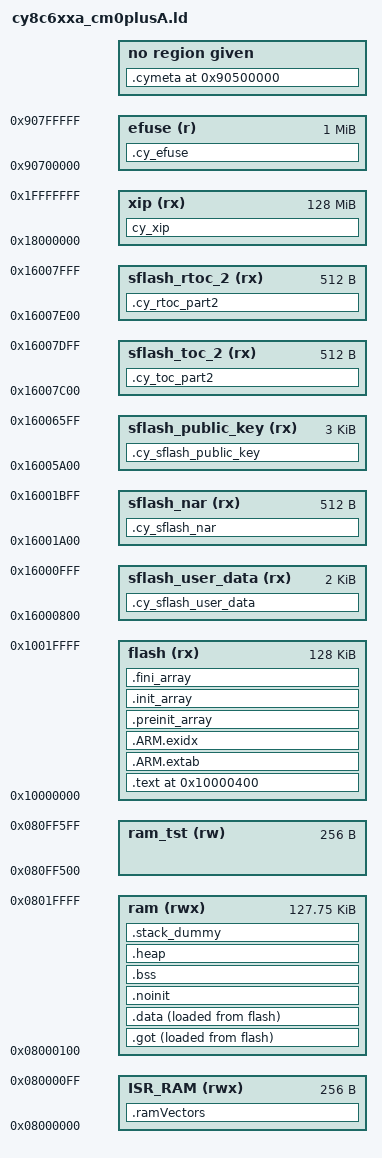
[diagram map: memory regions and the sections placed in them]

/**       ___
 *   ___ / _ \
 *  / _ ' (_) |       __  _
 * | (_) ,___/       / _|(_)
 *  \___/  _  _ __  | |_  _  _ __    ___  _ __  __ _
 *        | || '_ \ |  _|| || '_ \  / _ \| '__|/ _' |
 *        | || | | || |  | || | | ||  __/| |  | (_| |
 *        |_||_| |_||_|  |_||_| |_| \___||_|   \__,_|
 *
 * @file cy8c6xxa_cm0plusA.ld            @brief linker script
 *
 * @author Autogenerated
 *
 * @copyright 2023 Infinera. All rights reserved.
 * Infinera Proprietary and Confidential.
 *
 * @details
 * This file was generated automatically, src cy8c6xxa_cm0plusA.ld.in for details
 * Please do not modify it manually
 *
 ***************************************************************************/

OUTPUT_FORMAT ("elf32-littlearm", "elf32-bigarm", "elf32-littlearm")
SEARCH_DIR(.)
GROUP(-lgcc -lc -lnosys)
ENTRY(Reset_Handler)


STACK_SIZE = 0x1000;






EXTERN(Reset_Handler)




MEMORY
{







    ISR_RAM (rwx) : ORIGIN = 0x08000000, LENGTH = 0x100
    ram (rwx) : ORIGIN = 0x08000100, LENGTH = 0x1FF00
    ram_tst (rw) : ORIGIN = 0x080FF500, LENGTH = 0x100
    flash (rx) : ORIGIN = (0x10000000), LENGTH = 0x20000
    sflash_user_data (rx) : ORIGIN = 0x16000800, LENGTH = 0x800
    sflash_nar (rx) : ORIGIN = 0x16001A00, LENGTH = 0x200
    sflash_public_key (rx) : ORIGIN = 0x16005A00, LENGTH = 0xC00
    sflash_toc_2 (rx) : ORIGIN = 0x16007C00, LENGTH = 0x200
    sflash_rtoc_2 (rx) : ORIGIN = 0x16007E00, LENGTH = 0x200
    xip (rx) : ORIGIN = 0x18000000, LENGTH = 0x8000000
    efuse (r) : ORIGIN = 0x90700000, LENGTH = 0x100000
}
__flash_begin = ORIGIN(flash) + 0x400;
__flash_end = ORIGIN(flash) + LENGTH(flash);


GROUP(libgcc.a libc.a libm.a libnosys.a)
SECTIONS
{

    .text ORIGIN(flash) + 0x400 :
    {
       __flash_vector_table_begin = . ;
       KEEP(*(.vectors))
       __flash_vector_table_end = .;

        *(.text*)

        KEEP(*(.init))
        KEEP(*(.fini))


        *crtbegin.o(.ctors)
        *crtbegin?.o(.ctors)
        *(EXCLUDE_FILE(*crtend?.o *crtend.o) .ctors)
        *(SORT(.ctors.*))
        *(.ctors)


        *crtbegin.o(.dtors)
        *crtbegin?.o(.dtors)
        *(EXCLUDE_FILE(*crtend?.o *crtend.o) .dtors)
        *(SORT(.dtors.*))
        *(.dtors)


        *(.rodata .rodata.* .constdata .constdata.* .conststring .conststring.*)

        KEEP(*(.eh_frame*))
        _etext = .;
    } > flash

    .ramVectors (NOLOAD) : ALIGN(8)
    {
        __ram_vector_table_begin = .;
        KEEP(*(.ram_vectors))
        __ram_vector_table_end = .;
    } >ISR_RAM


    .got :
    {
        . = ALIGN(4);
        *(.got)
        *(.got.plt)
        KEEP(*(.igot.plt))
        . = ALIGN(4);
    } >ram AT > flash
    __flash_global_offset_table_begin = LOADADDR(.got) ;
    __flash_global_offset_table_end = __flash_global_offset_table_begin + SIZEOF(.got) ;
    __ram_global_offset_table_begin = ADDR(.got) ;
    __ram_global_offset_table_end = __ram_global_offset_table_begin + SIZEOF(.got) ;


    .ARM.extab :
    {
        . = ALIGN(4);
        *(.ARM.extab* .gnu.linkonce.armextab.*)
        . = ALIGN(4);
    } > flash

    .ARM.exidx :
    {
        . = ALIGN(4);
        __exidx_start = .;
        *(.ARM.exidx* .gnu.linkonce.armexidx.*)
        __exidx_end = .;
    } > flash

    .preinit_array :
  {
    . = ALIGN(4);
    PROVIDE_HIDDEN (__preinit_array_start = .);
    KEEP (*(.preinit_array*))
    PROVIDE_HIDDEN (__preinit_array_end = .);
    . = ALIGN(4);
  } >flash

  .init_array :
  {
    . = ALIGN(4);
    PROVIDE_HIDDEN (__init_array_start = .);
    KEEP (*(SORT(.init_array.*)))
    KEEP (*(.init_array*))
    PROVIDE_HIDDEN (__init_array_end = .);
    . = ALIGN(4);
  } >flash

  .fini_array :
  {
    . = ALIGN(4);
    PROVIDE_HIDDEN (__fini_array_start = .);
    KEEP (*(SORT(.fini_array.*)))
    KEEP (*(.fini_array*))
    PROVIDE_HIDDEN (__fini_array_end = .);
    . = ALIGN(4);
  } >flash


    _sidata = LOADADDR(.data);
    .data :
    {
        . = ALIGN(4);
        __data_start__ = .;

        *(vtable)
        *(.data*)

        . = ALIGN(4);
        KEEP(*(.jcr*))
        . = ALIGN(4);

        KEEP(*(.cy_ramfunc*))
        . = ALIGN(4);

        __data_end__ = .;

    } > ram AT>flash





    .noinit (NOLOAD) : ALIGN(8)
    {
      KEEP(*(.noinit))
    } > ram
    .bss (NOLOAD):
    {
        . = ALIGN(4);
        __bss_start__ = .;
        *(.bss*)
        *(COMMON)
        . = ALIGN(4);
        __bss_end__ = .;
    } > ram


    .heap (NOLOAD):
    {
        __HeapBase = .;
        __end__ = .;
        end = __end__;
        KEEP(*(.heap*))
        . = ORIGIN(ram) + LENGTH(ram) - STACK_SIZE;
        __HeapLimit = .;
    } > ram




    .stack_dummy (NOLOAD):
    {
        KEEP(*(.stack*))
    } > ram




    __StackTop = ORIGIN(ram) + LENGTH(ram);
    __StackLimit = __StackTop - SIZEOF(.stack_dummy);
    PROVIDE(__stack = __StackTop);


    ASSERT(__StackLimit >= __HeapLimit, "region RAM overflowed with stack")



    .cy_sflash_user_data :
    {
        KEEP(*(.cy_sflash_user_data))
    } > sflash_user_data



    .cy_sflash_nar :
    {
        KEEP(*(.cy_sflash_nar))
    } > sflash_nar



    .cy_sflash_public_key :
    {
        KEEP(*(.cy_sflash_public_key))
    } > sflash_public_key



    .cy_toc_part2 :
    {
        KEEP(*(.cy_toc_part2))
    } > sflash_toc_2



    .cy_rtoc_part2 :
    {
        KEEP(*(.cy_rtoc_part2))
    } > sflash_rtoc_2





    cy_xip :
    {
        __cy_xip_start = .;
        KEEP(*(.cy_xip))
        __cy_xip_end = .;
    } > xip



    .cy_efuse :
    {
        KEEP(*(.cy_efuse))
    } > efuse





    .cymeta 0x90500000 : { KEEP(*(.cymeta)) } :NONE
}




__cy_memory_0_start = (0x10000000);
__cy_memory_0_length = 0x00200000;
__cy_memory_0_row_size = 0x200;


__cy_memory_1_start = 0x14000000;
__cy_memory_1_length = 0x8000;
__cy_memory_1_row_size = 0x200;


__cy_memory_2_start = 0x16000000;
__cy_memory_2_length = 0x8000;
__cy_memory_2_row_size = 0x200;


__cy_memory_3_start = 0x18000000;
__cy_memory_3_length = 0x08000000;
__cy_memory_3_row_size = 0x200;


__cy_memory_4_start = 0x90700000;
__cy_memory_4_length = 0x100000;
__cy_memory_4_row_size = 1;
